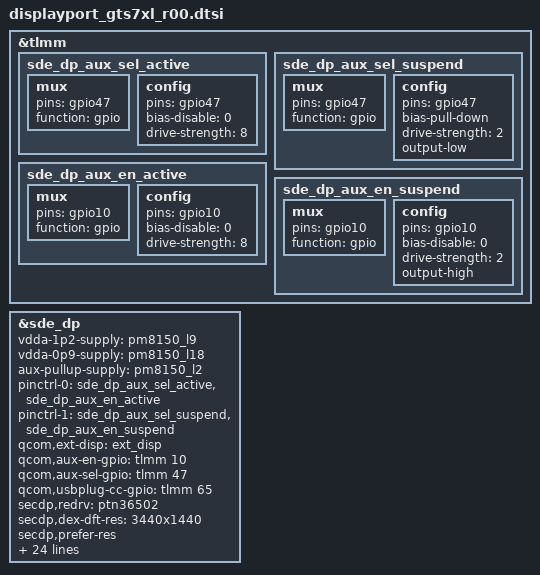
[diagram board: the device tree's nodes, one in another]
/* Copyright (c) 2016-2019, The Linux Foundation. All rights reserved.
 *
 * This program is free software; you can redistribute it and/or modify
 * it under the terms of the GNU General Public License version 2 and
 * only version 2 as published by the Free Software Foundation.
 *
 * This program is distributed in the hope that it will be useful,
 * but WITHOUT ANY WARRANTY; without even the implied warranty of
 * MERCHANTABILITY or FITNESS FOR A PARTICULAR PURPOSE.  See the
 * GNU General Public License for more details.
 */

/* SEC displayport setting */
&tlmm {
	/delete-node/ sde_dp_aux_active;
	/delete-node/ sde_dp_aux_suspend;
	/delete-node/ sde_dp_usbplug_cc_active;
	/delete-node/ sde_dp_usbplug_cc_suspend;

	sde_dp_aux_sel_active: sde_dp_aux_sel_active {
		mux {
			pins = "gpio47";
			function = "gpio";
		};

		config {
			pins = "gpio47";
			bias-disable = <0>; /* no pull */
			drive-strength = <8>;
		};
	};

	sde_dp_aux_sel_suspend: sde_dp_aux_sel_suspend {
		 mux {
			pins = "gpio47";
			function = "gpio";
		 };

		 config {
			pins = "gpio47";
			bias-pull-down;
			drive-strength = <2>;
			output-low;
		 };
	};

	sde_dp_aux_en_active: sde_dp_aux_en_active {
		mux {
			pins = "gpio10";
			function = "gpio";
		};

		config {
			pins = "gpio10";
			bias-disable = <0>; /* no pull */
			drive-strength = <8>;
		};
	};

	sde_dp_aux_en_suspend: sde_dp_aux_en_suspend {
		mux {
			pins = "gpio10";
			function = "gpio";
		};

		config {
			pins = "gpio10";
			bias-disable = <0>; /* no pull */
			drive-strength = <2>;
			output-high;
		};
	};
};

&sde_dp {
	vdda-1p2-supply = <&pm8150_l9>;
	vdda-0p9-supply = <&pm8150_l18>;
	aux-pullup-supply = <&pm8150_l2>;

	pinctrl-names = "mdss_dp_active", "mdss_dp_sleep";
	pinctrl-0 = <&sde_dp_aux_sel_active &sde_dp_aux_en_active>;
	pinctrl-1 = <&sde_dp_aux_sel_suspend &sde_dp_aux_en_suspend>;

	qcom,ext-disp = <&ext_disp>;

	qcom,aux-en-gpio = <&tlmm 10 0>;
	qcom,aux-sel-gpio = <&tlmm 47 0>;
	qcom,usbplug-cc-gpio = <&tlmm 65 0>;

	/*secdp,cc-dir-inv;*/
	/*secdp,aux-sel-inv;*/
	secdp,redrv = "ptn36502";
	secdp,dex-dft-res = "3440x1440";
	secdp,prefer-res;

	secdp,vm-pre-emphasis-0   = [00 0d 15 ff];
	secdp,vm-pre-emphasis-1   = [00 0d 15 ff];
	secdp,vm-pre-emphasis-2   = [00 0c ff ff];
	secdp,vm-pre-emphasis-3   = [ff ff ff ff];

	secdp,vm-voltage-swing-0  = [07 0f 14 ff];
	secdp,vm-voltage-swing-1  = [11 1d 1f ff];
	secdp,vm-voltage-swing-2  = [18 1f ff ff];
	secdp,vm-voltage-swing-3  = [ff ff ff ff];

	secdp,pre-emp-hbr2-hbr3-0 = [00 0c 14 1a];
	secdp,pre-emp-hbr2-hbr3-1 = [00 0c 14 ff];
	secdp,pre-emp-hbr2-hbr3-2 = [00 0d ff ff];
	secdp,pre-emp-hbr2-hbr3-3 = [ff ff ff ff];

	secdp,swing-hbr2-hbr3-0   = [09 11 19 1f];
	secdp,swing-hbr2-hbr3-1   = [12 1a 1f ff];
	secdp,swing-hbr2-hbr3-2   = [1d 1f ff ff];
	secdp,swing-hbr2-hbr3-3   = [ff ff ff ff];

	secdp,pre-emp-hbr-rbr-0   = [00 0b 13 19];
	secdp,pre-emp-hbr-rbr-1   = [00 0c 14 ff];
	secdp,pre-emp-hbr-rbr-2   = [00 0d ff ff];
	secdp,pre-emp-hbr-rbr-3   = [ff ff ff ff];

	secdp,swing-hbr-rbr-0     = [0a 11 19 1f];
	secdp,swing-hbr-rbr-1     = [12 1a 1f ff];
	secdp,swing-hbr-rbr-2     = [1d 1f ff ff];
	secdp,swing-hbr-rbr-3     = [ff ff ff ff];

/*
	qcom,phy-supply-entries {
		qcom,phy-supply-entry@0 {
			qcom,supply-name = "vdda-0p9";
			qcom,supply-min-voltage = <912000>;
			qcom,supply-max-voltage = <912000>;
		};
	};
*/
};
